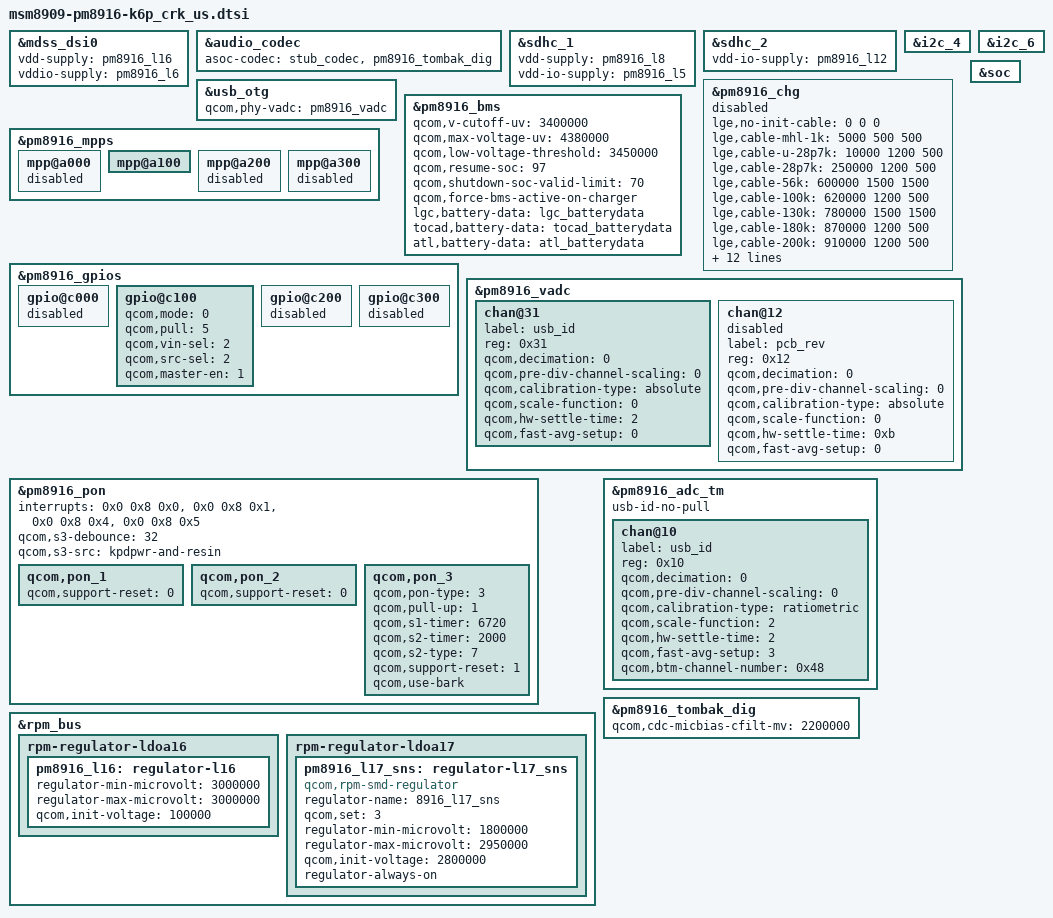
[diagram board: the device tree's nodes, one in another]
/* Copyright (c) 2014, The Linux Foundation. All rights reserved.
 *
 * This program is free software; you can redistribute it and/or modify
 * it under the terms of the GNU General Public License version 2 and
 * only version 2 as published by the Free Software Foundation.
 *
 * This program is distributed in the hope that it will be useful,
 * but WITHOUT ANY WARRANTY; without even the implied warranty of
 * MERCHANTABILITY or FITNESS FOR A PARTICULAR PURPOSE.  See the
 * GNU General Public License for more details.
 */

#include "pm8916-vibrator.dtsi"
#include "pm8916-led.dtsi"

&mdss_dsi0 {
	vdd-supply = <&pm8916_l16>;
	vddio-supply = <&pm8916_l6>;
};

&audio_codec {
	asoc-codec = <&stub_codec>, <&pm8916_tombak_dig>;
};

&sdhc_1 {
	vdd-supply = <&pm8916_l8>;
	vdd-io-supply = <&pm8916_l5>;
};

&sdhc_2 {
	vdd-io-supply = <&pm8916_l12>;
};

&i2c_4 {
};

&i2c_6 {
};

&usb_otg {
	qcom,phy-vadc = <&pm8916_vadc>;
};

&pm8916_chg {
	status = "disabled";

	/* ref resistance 200K */
	lge,no-init-cable = <0 0 0>;
	lge,cable-mhl-1k = <5000 500 500>;
	lge,cable-u-28p7k = <10000 1200 500>;
	lge,cable-28p7k = <250000 1200 500>;
	lge,cable-56k = <600000 1500 1500>;
	lge,cable-100k = <620000 1200 500>;
	lge,cable-130k = <780000 1500 1500>;
	lge,cable-180k = <870000 1200 500>;
	lge,cable-200k = <910000 1200 500>;
	lge,cable-220k = <960000 1200 500>;
	lge,cable-270k = <1050000 1200 500>;
	lge,cable-330k = <1150000 1200 500>;
	lge,cable-620k = <1380000 1200 500>;
	lge,cable-910k = <1630000 1500 1500>;
	lge,cable-none = <1900000 1200  500>;

	qcom,vddmax-mv = <4350>;
	qcom,vddsafe-mv = <4380>;
	qcom,vinmin-mv = <4470>;
	qcom,tchg-mins = <480>;
	qcom,btc-disabled;
	qcom,disable-vbatdet-based-recharge;
	/delete-property/ qcom,thermal-mitigation;
	/delete-property/ qcom,cool-bat-decidegc;
	/delete-property/ qcom,warm-bat-decidegc;
};

&pm8916_bms {
	status = "ok";
	qcom,v-cutoff-uv = <3400000>;
	qcom,max-voltage-uv = <4380000>;
	qcom,low-voltage-threshold = <3450000>;
	qcom,resume-soc = <97>;
	qcom,shutdown-soc-valid-limit = <70>;
	qcom,force-bms-active-on-charger;
	lgc,battery-data = <&lgc_batterydata>;
	tocad,battery-data = <&tocad_batterydata>;
	atl,battery-data = <&atl_batterydata>;
};

&pm8916_mpps {
	mpp@a000 { /* MPP 1 */
		/* VDD_PX */
		status = "disabled";
	};

	mpp@a100 { /* MPP 2 */
		/* Backlight PWM */
		status = "ok";
	};

	mpp@a200 { /* MPP 3 */
		/* VREF DAC */
		status = "disabled";
	};

	mpp@a300 { /* MPP 4 */
		/* HR LED */
		status = "disabled";
	};
};

&pm8916_gpios {
	gpio@c000 { /* GPIO 1 */
		/* Battery UICC Alarm */
		status = "disabled";
	};

	gpio@c100 { /* GPIO 2 */
		/* NFC_CLK_REQ */
		qcom,mode = <0>; /* QPNP_PIN_MODE_DIG_IN */
		qcom,pull = <5>; /* QPNP_PIN_PULL_NO */
		qcom,vin-sel = <2>; /* QPNP_PIN_VIN2 */
		qcom,src-sel = <2>; /* QPNP_PIN_SEL_FUNC_1 */
		qcom,master-en = <1>;
	};

	gpio@c200 { /* GPIO 3 */
		/* External regulator control for WTR */
		status = "disabled";
	};

	gpio@c300 { /* GPIO 4 */
		/* External regulator control for APC */
		status = "disabled";
	};
};

&pm8916_vadc {
	chan@31 {
		label = "usb_id";
		reg = <0x31>;
		qcom,decimation = <0>;
		qcom,pre-div-channel-scaling = <0>;
		qcom,calibration-type = "absolute";
		qcom,scale-function = <0>;
		qcom,hw-settle-time = <2>;
		qcom,fast-avg-setup = <0>;
	};

	chan@12 {
		status = "disabled";
		label = "pcb_rev";
		reg = <0x12>;
		qcom,decimation = <0>;
		qcom,pre-div-channel-scaling = <0>;
		qcom,calibration-type = "absolute";
		qcom,scale-function = <0>;
		qcom,hw-settle-time = <0xb>;
		qcom,fast-avg-setup = <0>;
	};
};

&pm8916_pon {
	status = "ok";
	interrupts = <0x0 0x8 0x0>,
		     <0x0 0x8 0x1>,
		     <0x0 0x8 0x4>,
		     <0x0 0x8 0x5>;
	interrupt-names = "kpdpwr", "resin",
		"resin-bark", "kpdpwr-resin-bark";
	qcom,s3-debounce = <32>;
	qcom,s3-src = "kpdpwr-and-resin";

	qcom,pon_1 {
		status = "ok";
		qcom,support-reset = <0>;
	};
	qcom,pon_2 {
		status = "ok";
		qcom,support-reset = <0>;
	};
	qcom,pon_3 {
		status = "ok";
		qcom,pon-type = <3>;
		qcom,pull-up = <1>;
		qcom,s1-timer = <6720>;
		qcom,s2-timer = <2000>;
		qcom,s2-type = <7>;
		qcom,support-reset = <1>;
		qcom,use-bark;
	};
};

&soc {
};

/* RPM controlled regulators */
&rpm_bus {
	/* PM8916 3V0_VREG_L16 LCD VDD 3.0V */
	rpm-regulator-ldoa16 {
		status = "okay";
		pm8916_l16: regulator-l16 {
			regulator-min-microvolt = <3000000>;
			regulator-max-microvolt = <3000000>;
			qcom,init-voltage = <100000>;
			status = "okay";
		};
	};

	rpm-regulator-ldoa17 {
		status = "ok";
		pm8916_l17_sns: regulator-l17_sns {
			status = "ok";
			compatible = "qcom,rpm-smd-regulator";
			regulator-name = "8916_l17_sns";
			qcom,set = <3>;
			regulator-min-microvolt = <1800000>;
			regulator-max-microvolt = <2950000>;
			qcom,init-voltage = <2800000>;
			regulator-always-on;
			};
	};
};
&pm8916_adc_tm {
	usb-id-no-pull;
	chan@10 {
		label = "usb_id";
		reg = <0x10>;
		qcom,decimation = <0>;
		qcom,pre-div-channel-scaling = <0>;
		qcom,calibration-type = "ratiometric";
		qcom,scale-function = <2>;
		qcom,hw-settle-time = <2>;
		qcom,fast-avg-setup = <3>;
		qcom,btm-channel-number = <0x48>;
	};
};

&pm8916_tombak_dig {
    qcom,cdc-micbias-cfilt-mv = <2200000>; /* Headset MIC BIAS V2.2 */
};
